# PIC32CX2051MTSH128 device description
Architecture: CORTEX-M4; Family: PIC32CXMT; Series: PIC32CXMTSH
Registers are 32-bit, read-write, no defined reset value unless marked. A register's access mark holds for its fields unless they carry their own. Offsets are from the block's base; [hi:lo] are bit positions; {n}, {i} and the like mark numbered series.

## GPNVMBITS (FUSES module)
Instances: GPNVMBITS 0 in fuses
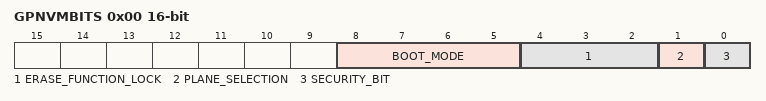
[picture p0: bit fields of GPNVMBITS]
0x00 GPNVMBITS 16-bit
  [8:5] BOOT_MODE — Boot Mode Selection
  [4:2] ERASE_FUNCTION_LOCK — Hardware Erase Function Lock
  [1] PLANE_SELECTION — Memory Plane Selection
  [0] SECURITY_BIT ro

## LOCKBIT
Instances: LOCKBIT 0 in lockbits
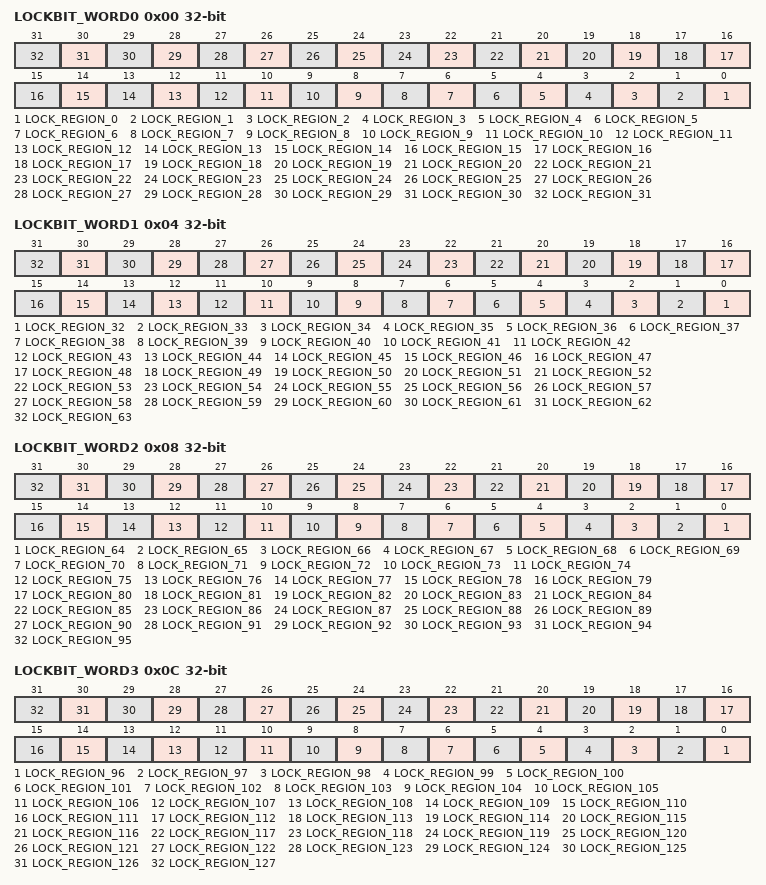
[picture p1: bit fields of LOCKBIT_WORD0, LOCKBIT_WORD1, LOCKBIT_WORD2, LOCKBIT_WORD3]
0x00 LOCKBIT_WORD0 — Lock Bits Word 0
  [n] LOCK_REGION_{n} (n=0..31)
0x04 LOCKBIT_WORD1 — Lock Bits Word 1
  [n-32] LOCK_REGION_{n} (n=32..63)
0x08 LOCKBIT_WORD2 — Lock Bits Word 2
  [n-64] LOCK_REGION_{n} (n=64..95)
0x0C LOCKBIT_WORD3 — Lock Bits Word 3
  [n-96] LOCK_REGION_{n} (n=96..127)
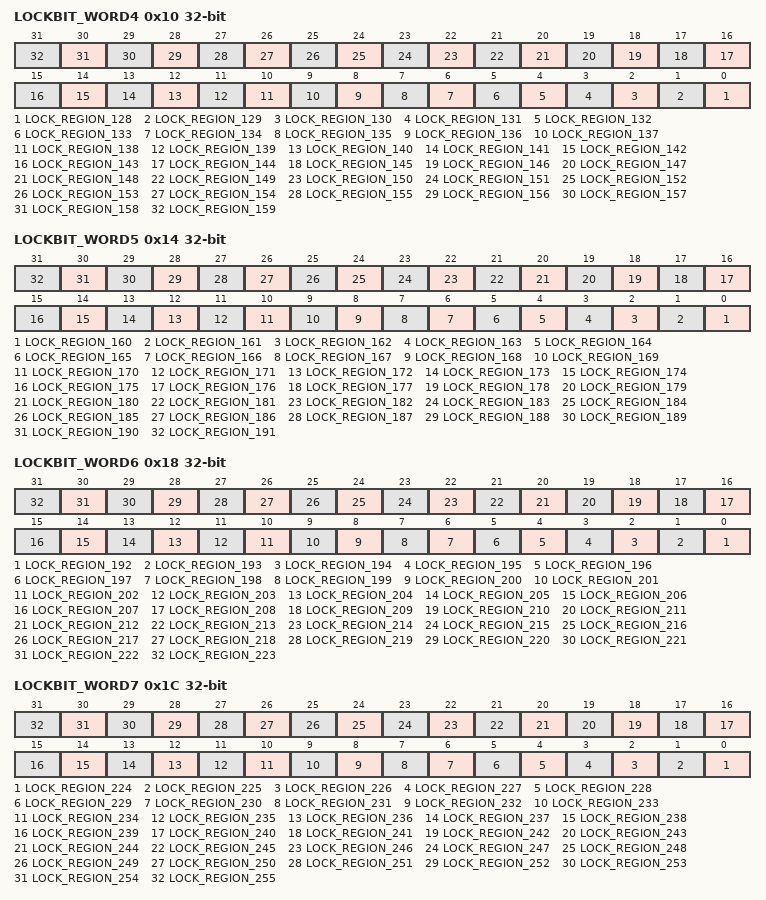
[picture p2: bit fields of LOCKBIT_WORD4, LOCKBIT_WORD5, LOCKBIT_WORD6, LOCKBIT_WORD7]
0x10 LOCKBIT_WORD4 — Lock Bits Word 4
  [n-128] LOCK_REGION_{n} (n=128..159)
0x14 LOCKBIT_WORD5 — Lock Bits Word 5
  [n-160] LOCK_REGION_{n} (n=160..191)
0x18 LOCKBIT_WORD6 — Lock Bits Word 6
  [n-192] LOCK_REGION_{n} (n=192..223)
0x1C LOCKBIT_WORD7 — Lock Bits Word 7
  [n-224] LOCK_REGION_{n} (n=224..255)
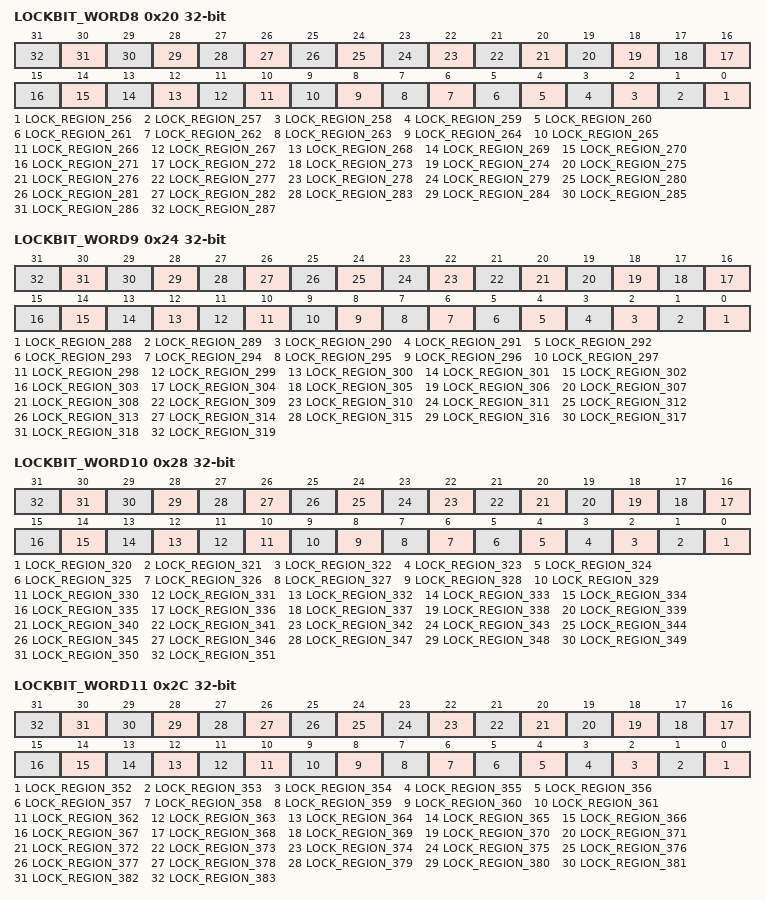
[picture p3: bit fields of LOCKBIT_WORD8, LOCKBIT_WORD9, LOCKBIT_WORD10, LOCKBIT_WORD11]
0x20 LOCKBIT_WORD8 — Lock Bits Word 8
  [n-256] LOCK_REGION_{n} (n=256..287)
0x24 LOCKBIT_WORD9 — Lock Bits Word 9
  [n-288] LOCK_REGION_{n} (n=288..319)
0x28 LOCKBIT_WORD10 — Lock Bits Word 10
  [n-320] LOCK_REGION_{n} (n=320..351)
0x2C LOCKBIT_WORD11 — Lock Bits Word 11
  [n-352] LOCK_REGION_{n} (n=352..383)
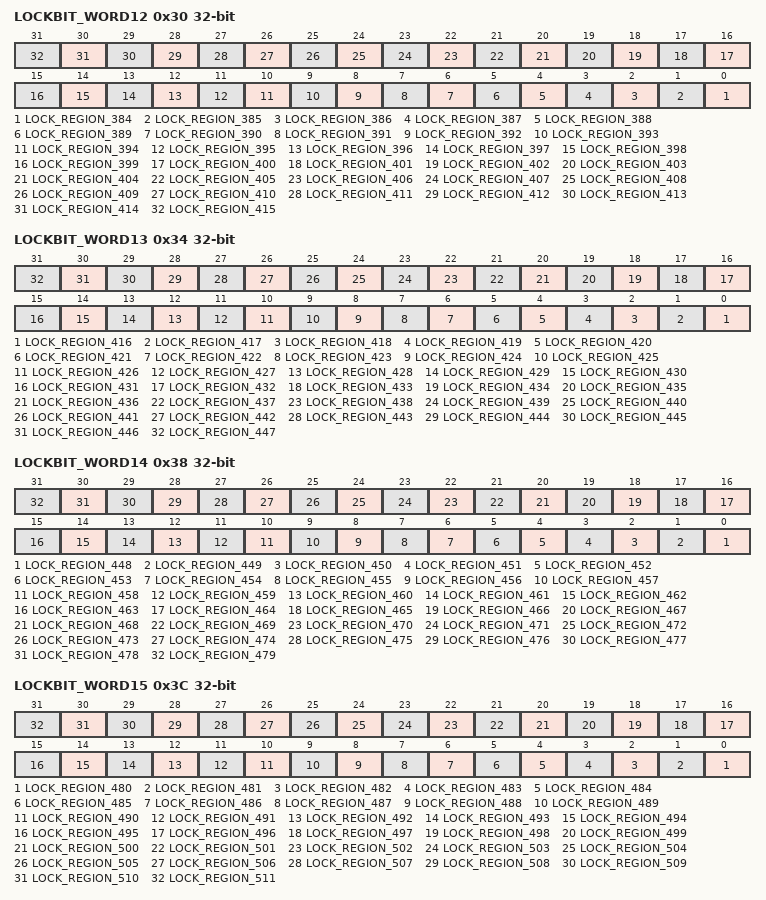
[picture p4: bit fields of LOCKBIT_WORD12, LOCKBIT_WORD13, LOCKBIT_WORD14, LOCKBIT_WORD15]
0x30 LOCKBIT_WORD12 — Lock Bits Word 12
  [n-384] LOCK_REGION_{n} (n=384..415)
0x34 LOCKBIT_WORD13 — Lock Bits Word 13
  [n-416] LOCK_REGION_{n} (n=416..447)
0x38 LOCKBIT_WORD14 — Lock Bits Word 14
  [n-448] LOCK_REGION_{n} (n=448..479)
0x3C LOCKBIT_WORD15 — Lock Bits Word 15
  [n-480] LOCK_REGION_{n} (n=480..511)

## CoreDebug
Instances: CoreDebug 0xE000EDF0
0x00 DHCSR access not given — Debug Halting Control and Status Register
  [25] S_RESET_ST ro, [24] S_RETIRE_ST ro, [19] S_LOCKUP ro, [18] S_SLEEP ro, [17] S_HALT ro, [16] S_REGRDY ro, [31:16] DBGKEY wo, [5] C_SNAPSTALL rw, [3] C_MASKINTS rw, [2] C_STEP rw, [1] C_HALT rw, [0] C_DEBUGEN rw
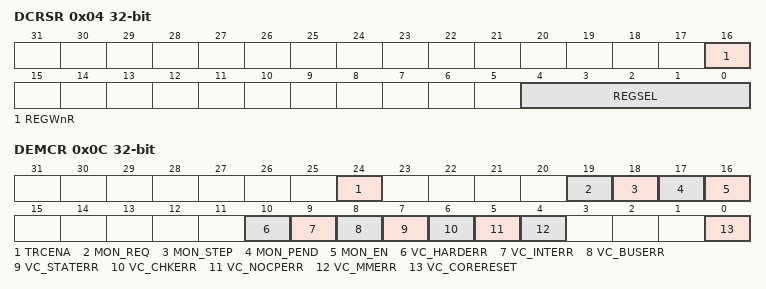
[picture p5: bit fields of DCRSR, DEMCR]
0x04 DCRSR wo — Debug Core Register Selector Register
  [16] REGWnR, [4:0] REGSEL
0x08 DCRDR — Debug Core Register Data Register
0x0C DEMCR — Debug Exception and Monitor Control Register
  [24] TRCENA, [19] MON_REQ, [18] MON_STEP, [17] MON_PEND, [16] MON_EN, [10] VC_HARDERR, [9] VC_INTERR, [8] VC_BUSERR, [7] VC_STATERR, [6] VC_CHKERR, [5] VC_NOCPERR, [4] VC_MMERR, [0] VC_CORERESET

## DWT — Data Watchpoint and Trace Register
Instances: DWT 0xE0001000
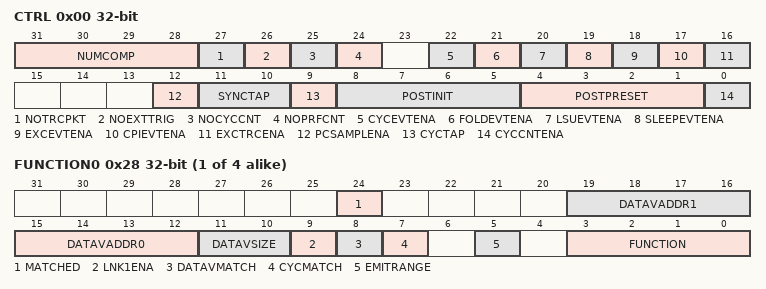
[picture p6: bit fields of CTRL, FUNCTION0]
0x00 CTRL — Control Register
  [31:28] NUMCOMP, [27] NOTRCPKT, [26] NOEXTTRIG, [25] NOCYCCNT, [24] NOPRFCNT, [22] CYCEVTENA, [21] FOLDEVTENA, [20] LSUEVTENA, [19] SLEEPEVTENA, [18] EXCEVTENA, [17] CPIEVTENA, [16] EXCTRCENA, [12] PCSAMPLENA, [11:10] SYNCTAP, [9] CYCTAP, [8:5] POSTINIT, [4:1] POSTPRESET, [0] CYCCNTENA
0x04 CYCCNT — Cycle Count Register
0x08 CPICNT — CPI Count Register
  [7:0] CPICNT
0x0C EXCCNT — Exception Overhead Count Register
  [7:0] EXCCNT
0x10 SLEEPCNT — Sleep Count Register
  [7:0] SLEEPCNT
0x14 LSUCNT — LSU Count Register
  [7:0] LSUCNT
0x18 FOLDCNT — Folded-instruction Count Register
  [7:0] FOLDCNT
0x1C PCSR ro — Program Counter Sample Register
{0x20+0x10*i} COMP{i} (i=0..3) — Comparator Register {i}
{0x24+0x10*i} MASK{i} (i=0..3) — Mask Register {i}
  [4:0] MASK
{0x28+0x10*i} FUNCTION{i} (i=0..3) — Function Register {i}
  [24] MATCHED, [19:16] DATAVADDR1, [15:12] DATAVADDR0, [11:10] DATAVSIZE, [9] LNK1ENA, [8] DATAVMATCH, [7] CYCMATCH, [5] EMITRANGE, [3:0] FUNCTION

## FPU — Floating Point Unit
Instances: FPU 0xE000EF30
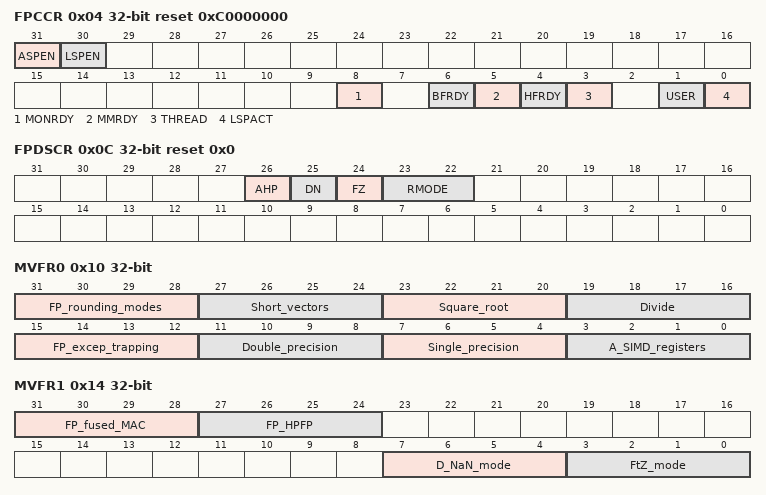
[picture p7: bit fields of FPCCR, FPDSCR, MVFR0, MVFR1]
0x04 FPCCR reset 0xC0000000 — Floating-Point Context Control Register
  [31] ASPEN, [30] LSPEN, [8] MONRDY, [6] BFRDY, [5] MMRDY, [4] HFRDY, [3] THREAD, [1] USER, [0] LSPACT
0x08 FPCAR — Floating-Point Context Address Register
  [31:3] ADDRESS — Address for FP registers in exception stack frame
0x0C FPDSCR reset 0x0 — Floating-Point Default Status Control Register
  [26] AHP — Default value for FPSCR.AHP
  [25] DN — Default value for FPSCR.DN
  [24] FZ — Default value for FPSCR.FZ
  [23:22] RMODE — Default value for FPSCR.RMODE
    0=RN (Round to Nearest); 1=RP (Round towards Positive Infinity); 2=RM (Round towards Negative Infinity); 3=RZ (Round towards Zero)
0x10 MVFR0 ro — Media and FP Feature Register 0
  [31:28] FP_rounding_modes, [27:24] Short_vectors, [23:20] Square_root, [19:16] Divide, [15:12] FP_excep_trapping, [11:8] Double_precision, [7:4] Single_precision, [3:0] A_SIMD_registers
0x14 MVFR1 ro — Media and FP Feature Register 1
  [31:28] FP_fused_MAC, [27:24] FP_HPFP, [7:4] D_NaN_mode, [3:0] FtZ_mode

## Notices in the file
Copyright %copyright_year% Microchip Technology Inc.
SPDX-License-Identifier: Apache-2.0
Licensed under the Apache License, Version 2.0 (the "License");
you may not use this file except in compliance with the License.
You may obtain a copy of the License at
http://www.apache.org/licenses/LICENSE-2.0
Unless required by applicable law or agreed to in writing, software
distributed under the License is distributed on an "AS IS" BASIS,
WITHOUT WARRANTIES OR CONDITIONS OF ANY KIND, either express or implied.
See the License for the specific language governing permissions and
limitations under the License.
